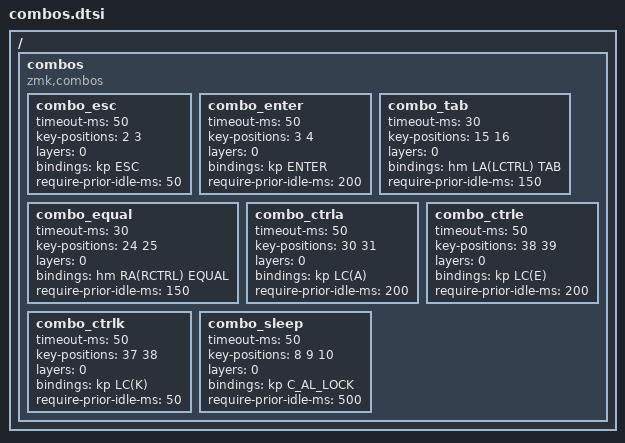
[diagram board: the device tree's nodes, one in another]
/*
   KEY POSITIONS
  ╭────────────────────────╮       ╭────────────────────────╮
  │LT5 LT4 LT3 LT2 LT1 LT0 │   A   │ RT0 RT1 RT2 RT3 RT4 RT5│
  │LM5 LM4 LM3 LM2 LM1 LM0 │ B C D │ RM0 RM1 RM2 RM3 RM4 RM5│
  │LB5 LB4 LB3 LB2 LB1 LB0 │  E F  │ RB0 RB1 RB2 RB3 RB4 RB5│
  ╰──────────╮ LH2 LH1 LH0 │       │ RH0 RH1 RH2 ╭──────────╯
             ╰─────────────╯       ╰─────────────╯ 
*/


/ {

    combos {
        compatible = "zmk,combos";

        combo_esc {
            timeout-ms = <50>;  // all keys must be pressed within 'timeout-ms'
            key-positions = <2 3>;
            // global-quick-tap-ms = <75>;
            layers = <0>;
            bindings = <&kp ESC>;
            require-prior-idle-ms = <50>;
        };

        combo_enter {
            timeout-ms = <50>;
            key-positions = <3 4>;
            // global-quick-tap-ms = <75>;
            layers = <0>;
            bindings = <&kp ENTER>;
            require-prior-idle-ms = <200>;
        };

        combo_tab {
            timeout-ms = <30>;
            key-positions = <15 16>;
            layers = <0>;
            bindings = <&hm LA(LCTRL) TAB>;
            require-prior-idle-ms = <150>;
        };

        combo_equal {
            timeout-ms = <30>;
            key-positions = <24 25>;
            layers = <0>;
            bindings = <&hm RA(RCTRL) EQUAL>;
            require-prior-idle-ms = <150>;
        };

        combo_ctrla {
            timeout-ms = <50>;
            key-positions = <30 31>;
            layers = <0>;
            bindings = <&kp LC(A)>;
            require-prior-idle-ms = <200>;
        };

        combo_ctrle {
            timeout-ms = <50>;
            key-positions = <38 39>;
            layers = <0>;
            bindings = <&kp LC(E)>;
            require-prior-idle-ms = <200>;
        };

        combo_ctrlk {
            timeout-ms = <50>;  
            key-positions = <37 38>;
            layers = <0>;
            bindings = <&kp LC(K)>;
            require-prior-idle-ms = <50>;
		};

        combo_sleep {
            timeout-ms = <50>;
            key-positions = <8 9 10>;
            layers = <0>;
            bindings = <&kp C_AL_LOCK>;
            require-prior-idle-ms = <500>;
        };
    };
};
